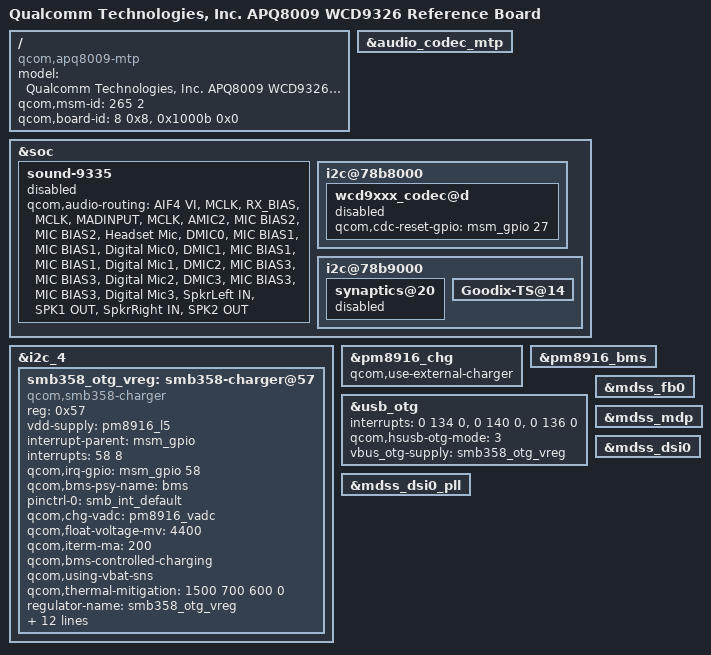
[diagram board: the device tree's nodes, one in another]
/*
 * Copyright (c) 2016-2017, The Linux Foundation. All rights reserved.
 *
 * This program is free software; you can redistribute it and/or modify
 * it under the terms of the GNU General Public License version 2 and
 * only version 2 as published by the Free Software Foundation.
 *
 * This program is distributed in the hope that it will be useful,
 * but WITHOUT ANY WARRANTY; without even the implied warranty of
 * MERCHANTABILITY or FITNESS FOR A PARTICULAR PURPOSE.  See the
 * GNU General Public License for more details.
 */

/dts-v1/;

#include "msm8909-mtp.dtsi"
#include "msm8909-pm8916.dtsi"
#include "msm8909-pm8916-mtp.dtsi"
#include "apq8009-memory.dtsi"

/ {
	model = "Qualcomm Technologies, Inc. APQ8009 WCD9326 Reference Board";
	compatible = "qcom,apq8009-mtp", "qcom,apq8009", "qcom,mtp";
	qcom,msm-id = <265 2>;
	qcom,board-id= <8 0x8>,<0x1000b 0x0>;
};

&audio_codec_mtp {
	status = "ok";
};

&soc {
	sound-9335 {
                status = "disabled";
		qcom,audio-routing =
			"AIF4 VI", "MCLK",
			"RX_BIAS", "MCLK",
			"MADINPUT", "MCLK",
			"AMIC2", "MIC BIAS2",
			"MIC BIAS2", "Headset Mic",
			"DMIC0", "MIC BIAS1",
			"MIC BIAS1", "Digital Mic0",
			"DMIC1", "MIC BIAS1",
			"MIC BIAS1", "Digital Mic1",
			"DMIC2", "MIC BIAS3",
			"MIC BIAS3", "Digital Mic2",
			"DMIC3", "MIC BIAS3",
			"MIC BIAS3", "Digital Mic3",
			"SpkrLeft IN", "SPK1 OUT",
			"SpkrRight IN", "SPK2 OUT";
	};

	i2c@78b8000 {
		wcd9xxx_codec@d {
                        status = "disabled";
			qcom,cdc-reset-gpio = <&msm_gpio 27 0>;
		};
	};

	i2c@78b9000 {
		synaptics@20 {
			status = "disabled";
		};
	};
	i2c@78b9000 {
		Goodix-TS@14 {
			status = "ok";
		};
	};
};

&i2c_4 {
	smb358_otg_vreg: smb358-charger@57 {
		compatible = "qcom,smb358-charger";
		reg = <0x57>;
		vdd-supply = <&pm8916_l5>;
		interrupt-parent = <&msm_gpio>;
		interrupts = <58 8>;
		qcom,irq-gpio = <&msm_gpio 58 0x2008>;
		pinctrl-names = "default";
		qcom,bms-psy-name = "bms";
		pinctrl-0 = <&smb_int_default>;
		qcom,chg-vadc = <&pm8916_vadc>;
		
		qcom,float-voltage-mv = <4400>;
		qcom,iterm-ma = <200>;
		qcom,bms-controlled-charging;
		qcom,using-vbat-sns;
		qcom,thermal-mitigation = <1500 700 600 0>;
		regulator-name = "smb358_otg_vreg";
        qcom,cold-bat-decidegc = <0>;
		qcom,cool-bat-decidegc = <150>;
		qcom,warm-bat-decidegc = <450>;
		qcom,hot-bat-decidegc = <500>;
		qcom,bat-present-decidegc = <400>;
		qcom,cool-bat-ma  = <1500>;
		qcom,warm-bat-ma  = <1500>;
		qcom,fastchg-current-max-ma  = <2000>;
		qcom,recharge-mv = <100>;
		qcom,cool-bat-mv = <4400>;
		qcom,warm-bat-mv = <4100>;
		qcom,soc-delay-worker-time = <15000>;
	};
};

&pm8916_chg {
	status = "ok";
	qcom,use-external-charger;
};

&pm8916_bms {
	status = "ok";
};

&usb_otg {
	interrupts = <0 134 0>,<0 140 0>,<0 136 0>;
	interrupt-names = "core_irq", "async_irq", "phy_irq";

	qcom,hsusb-otg-mode = <3>;
	vbus_otg-supply = <&smb358_otg_vreg>;
};

&mdss_fb0 {
	status = "ok";
};

//delete by 101003082 for splash memory at 2018/05/21
&mdss_mdp {
	status = "ok";
};

&mdss_dsi0_pll {
	status = "ok";
};

&mdss_dsi0 {
	status = "ok";
};
